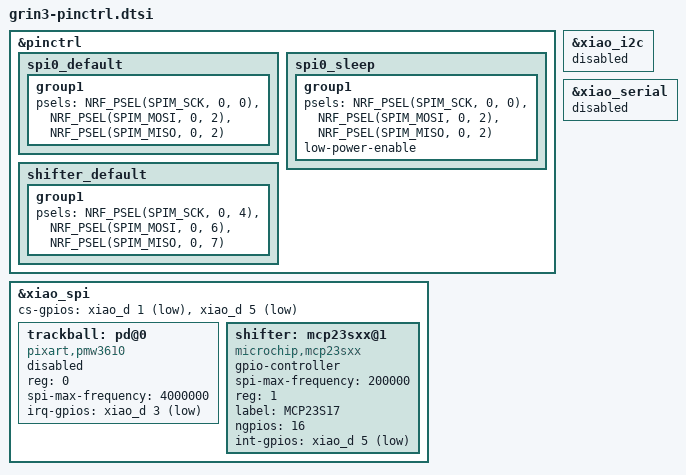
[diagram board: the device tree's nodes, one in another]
&pinctrl {
    spi0_default: spi0_default {
        group1 {
            psels = <NRF_PSEL(SPIM_SCK, 0, 0)>,
                <NRF_PSEL(SPIM_MOSI, 0, 2)>,
                <NRF_PSEL(SPIM_MISO, 0, 2)>;
        };
    };

    spi0_sleep: spi0_sleep {
        group1 {
            psels = <NRF_PSEL(SPIM_SCK, 0, 0)>,
                <NRF_PSEL(SPIM_MOSI, 0, 2)>,
                <NRF_PSEL(SPIM_MISO, 0, 2)>;
            low-power-enable;
        };
    };
    
    shifter_default: shifter_default {
        group1 {
            psels = <NRF_PSEL(SPIM_SCK, 0, 4)>,
                    <NRF_PSEL(SPIM_MOSI, 0, 6)>,
                    <NRF_PSEL(SPIM_MISO, 0, 7)>;
        };
    };
};

&xiao_spi {
    status = "okay";
    cs-gpios = <&xiao_d 1 GPIO_ACTIVE_LOW>,<&xiao_d 5 GPIO_ACTIVE_LOW>;

    trackball: pd@0 {
        status = "disabled";
        compatible = "pixart,pmw3610";
        reg = <0>;
        spi-max-frequency = <4000000>;
        irq-gpios = <&xiao_d 3 (GPIO_ACTIVE_LOW | GPIO_PULL_UP)>;
    };

    shifter: mcp23sxx@1 {
        status = "okay";
        compatible = "microchip,mcp23sxx";
        gpio-controller;
        spi-max-frequency = <200000>;
        reg = <1>;
        label = "MCP23S17";
        #gpio-cells = <2>;
        ngpios = <16>;
        int-gpios = <&xiao_d 5 GPIO_ACTIVE_LOW>;
    };
};

&xiao_i2c { status = "disabled"; };
&xiao_serial { status = "disabled"; };
